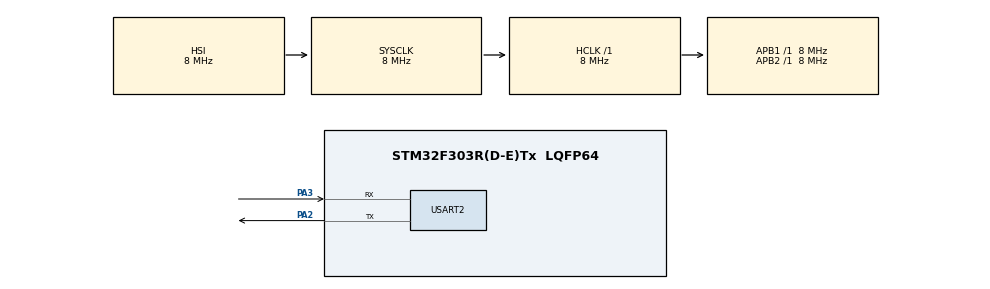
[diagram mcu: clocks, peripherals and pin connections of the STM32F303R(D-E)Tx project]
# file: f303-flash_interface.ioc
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Mcu.Family=STM32F3
RCC.CortexFreq_Value=8000000
ProjectManager.StackSize=0x400
PA3.Mode=Asynchronous
ProjectManager.TargetToolchain=STM32CubeIDE
RCC.USBFreq_Value=16000000
RCC.LSE_VALUE=32768
RCC.AHBFreq_Value=8000000
RCC.HSE_VALUE=8000000
board=custom
USART2.VirtualMode-Asynchronous=VM_ASYNC
RCC.APB2Freq_Value=8000000
Mcu.Name=STM32F303R(D-E)Tx
PA2.Signal=USART2_TX
RCC.SYSCLKFreq_VALUE=8000000
Mcu.Package=LQFP64
ProjectManager.HeapSize=0x200
RCC.HSI_VALUE=8000000
NVIC.PriorityGroup=NVIC_PRIORITYGROUP_4
PA2.Mode=Asynchronous
RCC.APB1Freq_Value=8000000
PA3.Signal=USART2_RX

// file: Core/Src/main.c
/* USER CODE BEGIN Header */
/**
  ******************************************************************************
  * @file           : main.c
  * @brief          : Main program body
  ******************************************************************************
  * @attention
  *
  * <h2><center>&copy; Copyright (c) 2021 STMicroelectronics.
  * All rights reserved.</center></h2>
  *
  * This software component is licensed by ST under BSD 3-Clause license,
  * the "License"; You may not use this file except in compliance with the
  * License. You may obtain a copy of the License at:
  *                        opensource.org/licenses/BSD-3-Clause
  *
  ******************************************************************************
  */
/* USER CODE END Header */
#include "main.h"

/* USER CODE BEGIN Includes */
#include <stdio.h>
#include <string.h>
#include <stdarg.h>

#include "stm32f3xx_hal.h"
#include "stm32f3xx_hal_flash_ex.h"
#include "stm32f3xx_hal_flash.h"
/* USER CODE END Includes */

UART_HandleTypeDef huart2;

void SystemClock_Config(void);
static void MX_GPIO_Init(void);
static void MX_USART2_UART_Init(void);
/* USER CODE BEGIN PFP */
extern void    FLASH_PageErase(uint32_t PageAddress);
/* USER CODE END PFP */

/* USER CODE BEGIN 0 */
void myprintf(const char *fmt, ...) {
	static char buffer[256];
	va_list args;
	va_start(args, fmt);
	vsnprintf(buffer, sizeof(buffer), fmt, args);
	va_end(args);

	int len = strlen(buffer);
	HAL_UART_Transmit(&huart2, (uint8_t*) buffer, len, -1);

}
/* USER CODE END 0 */

int main(void)
{

  /* MCU Configuration--------------------------------------------------------*/

  /* Reset of all peripherals, Initializes the Flash interface and the Systick. */
  HAL_Init();

  /* Configure the system clock */
  SystemClock_Config();

  /* Initialize all configured peripherals */
  MX_GPIO_Init();
  MX_USART2_UART_Init();

  /* Infinite loop */
  /* USER CODE BEGIN WHILE */
  uint32_t numbers[2] = {1, '6'};
  uint32_t address =  0x0807F7FCU;
//  uint32_t reg = 0;
//
//  if(HAL_FLASH_Unlock() != HAL_OK){
//	  while (1){
//		  myprintf("Mistakes were made\n");
//	  }
//  }
//
//  static FLASH_EraseInitTypeDef EraseInitStruct;
//      EraseInitStruct.TypeErase = FLASH_TYPEERASE_PAGES;
//      EraseInitStruct.PageAddress = address;
//      EraseInitStruct.NbPages = 1;
//      HAL_FLASHEx_Erase(&EraseInitStruct, &reg);
//
//      if(reg | 0xFFFFFFFF == 0xFFFFFFFF){
//    	  myprintf("Memory is gone yey\r\n");
//      }
//
//  //HAL_FLASH_Lock();
//
//  //HAL_FLASH_Unlock();
//
//  if(HAL_FLASH_Program(FLASH_TYPEPROGRAM_WORD, address, '1') != HAL_OK){
//	  myprintf("Could not write\r\n");
//  }
//
//  HAL_FLASH_Lock();
  // TODO test page transitions
  MRT_WriteDataToFlash(FLASH_TYPEPROGRAM_HALFWORD, address, numbers, 2);

  uint32_t *readData = (uint32_t *) address;

  myprintf("Yey %i and yey %i\r\n", *(readData), *(readData+1));

  while (1)
  {
    /* USER CODE END WHILE */

  }
}

void SystemClock_Config(void)
{
  RCC_OscInitTypeDef RCC_OscInitStruct = {0};
  RCC_ClkInitTypeDef RCC_ClkInitStruct = {0};
  RCC_PeriphCLKInitTypeDef PeriphClkInit = {0};

  /** Initializes the RCC Oscillators according to the specified parameters
  * in the RCC_OscInitTypeDef structure.
  */
  RCC_OscInitStruct.OscillatorType = RCC_OSCILLATORTYPE_HSI;
  RCC_OscInitStruct.HSIState = RCC_HSI_ON;
  RCC_OscInitStruct.HSICalibrationValue = RCC_HSICALIBRATION_DEFAULT;
  RCC_OscInitStruct.PLL.PLLState = RCC_PLL_NONE;
  if (HAL_RCC_OscConfig(&RCC_OscInitStruct) != HAL_OK)
  {
    Error_Handler();
  }
  /** Initializes the CPU, AHB and APB buses clocks
  */
  RCC_ClkInitStruct.ClockType = RCC_CLOCKTYPE_HCLK|RCC_CLOCKTYPE_SYSCLK
                              |RCC_CLOCKTYPE_PCLK1|RCC_CLOCKTYPE_PCLK2;
  RCC_ClkInitStruct.SYSCLKSource = RCC_SYSCLKSOURCE_HSI;
  RCC_ClkInitStruct.AHBCLKDivider = RCC_SYSCLK_DIV1;
  RCC_ClkInitStruct.APB1CLKDivider = RCC_HCLK_DIV1;
  RCC_ClkInitStruct.APB2CLKDivider = RCC_HCLK_DIV1;

  if (HAL_RCC_ClockConfig(&RCC_ClkInitStruct, FLASH_LATENCY_0) != HAL_OK)
  {
    Error_Handler();
  }
  PeriphClkInit.PeriphClockSelection = RCC_PERIPHCLK_USART2;
  PeriphClkInit.Usart2ClockSelection = RCC_USART2CLKSOURCE_PCLK1;
  if (HAL_RCCEx_PeriphCLKConfig(&PeriphClkInit) != HAL_OK)
  {
    Error_Handler();
  }
}

static void MX_USART2_UART_Init(void)
{

  huart2.Instance = USART2;
  huart2.Init.BaudRate = 38400;
  huart2.Init.WordLength = UART_WORDLENGTH_8B;
  huart2.Init.StopBits = UART_STOPBITS_1;
  huart2.Init.Parity = UART_PARITY_NONE;
  huart2.Init.Mode = UART_MODE_TX_RX;
  huart2.Init.HwFlowCtl = UART_HWCONTROL_NONE;
  huart2.Init.OverSampling = UART_OVERSAMPLING_16;
  huart2.Init.OneBitSampling = UART_ONE_BIT_SAMPLE_DISABLE;
  huart2.AdvancedInit.AdvFeatureInit = UART_ADVFEATURE_NO_INIT;
  if (HAL_UART_Init(&huart2) != HAL_OK)
  {
    Error_Handler();
  }

}

static void MX_GPIO_Init(void)
{

  /* GPIO Ports Clock Enable */
  __HAL_RCC_GPIOA_CLK_ENABLE();

}

void Error_Handler(void)
{
  __disable_irq();
  while (1)
  {
  }
}

/************************ (C) COPYRIGHT STMicroelectronics *****END OF FILE****/
